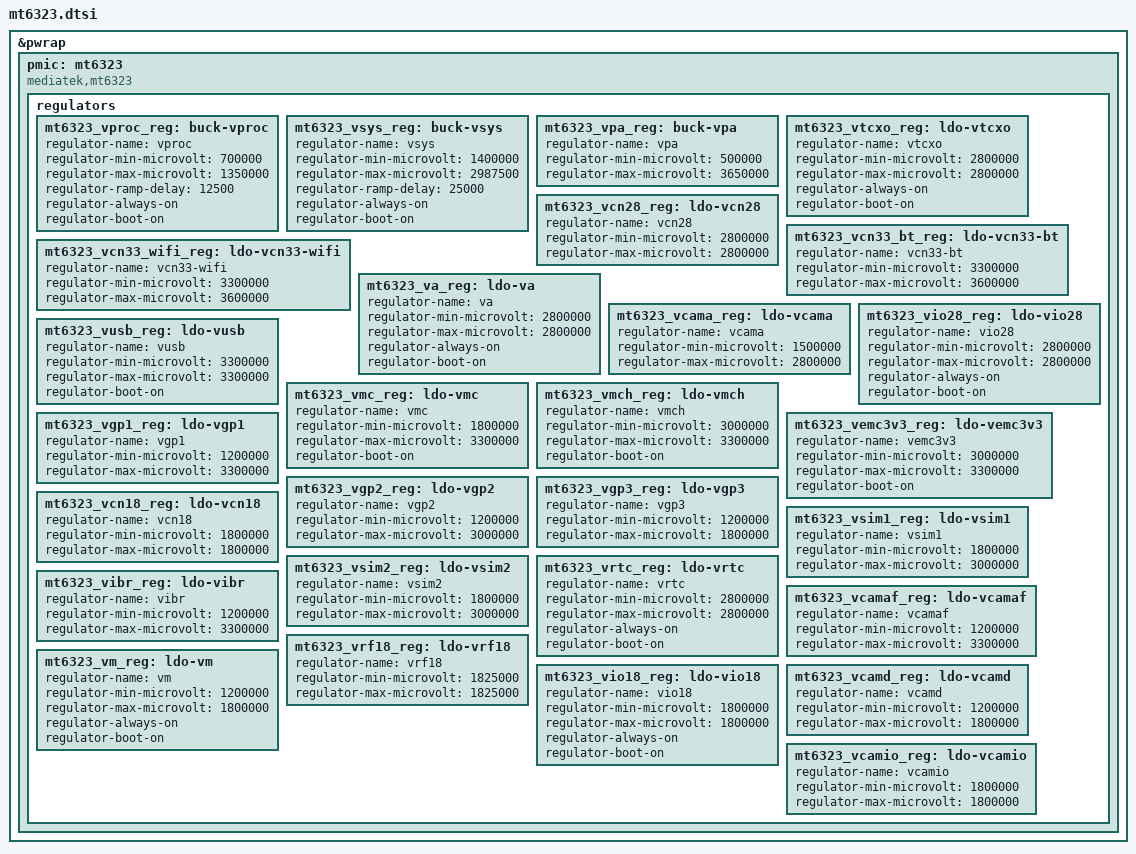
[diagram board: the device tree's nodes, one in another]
// SPDX-License-Identifier: GPL-2.0
/*
 * Copyright (c) 2017-2018 MediaTek Inc.
 * Author: John Crispin <john@phrozen.org>
 *	   Sean Wang <sean.wang@mediatek.com>
 * Copyright (c) 2026 Ben Grisdale <bengris32@protonmail.ch>
 */

&pwrap {
	pmic: mt6323 {
		compatible = "mediatek,mt6323";

		regulators {
			mt6323_vproc_reg: buck-vproc {
				regulator-name = "vproc";
				regulator-min-microvolt = <700000>;
				regulator-max-microvolt = <1350000>;
				regulator-ramp-delay = <12500>;
				regulator-always-on;
				regulator-boot-on;
			};

			mt6323_vsys_reg: buck-vsys {
				regulator-name = "vsys";
				regulator-min-microvolt = <1400000>;
				regulator-max-microvolt = <2987500>;
				regulator-ramp-delay = <25000>;
				regulator-always-on;
				regulator-boot-on;
			};

			mt6323_vpa_reg: buck-vpa {
				regulator-name = "vpa";
				regulator-min-microvolt = <500000>;
				regulator-max-microvolt = <3650000>;
			};

			mt6323_vtcxo_reg: ldo-vtcxo {
				regulator-name = "vtcxo";
				regulator-min-microvolt = <2800000>;
				regulator-max-microvolt = <2800000>;
				regulator-always-on;
				regulator-boot-on;
			};

			mt6323_vcn28_reg: ldo-vcn28 {
				regulator-name = "vcn28";
				regulator-min-microvolt = <2800000>;
				regulator-max-microvolt = <2800000>;
			};

			mt6323_vcn33_bt_reg: ldo-vcn33-bt {
				regulator-name = "vcn33-bt";
				regulator-min-microvolt = <3300000>;
				regulator-max-microvolt = <3600000>;
			};

			mt6323_vcn33_wifi_reg: ldo-vcn33-wifi {
				regulator-name = "vcn33-wifi";
				regulator-min-microvolt = <3300000>;
				regulator-max-microvolt = <3600000>;
			};

			mt6323_va_reg: ldo-va {
				regulator-name = "va";
				regulator-min-microvolt = <2800000>;
				regulator-max-microvolt = <2800000>;
				regulator-always-on;
				regulator-boot-on;
			};

			mt6323_vcama_reg: ldo-vcama {
				regulator-name = "vcama";
				regulator-min-microvolt = <1500000>;
				regulator-max-microvolt = <2800000>;
			};

			mt6323_vio28_reg: ldo-vio28 {
				regulator-name = "vio28";
				regulator-min-microvolt = <2800000>;
				regulator-max-microvolt = <2800000>;
				regulator-always-on;
				regulator-boot-on;
			};

			mt6323_vusb_reg: ldo-vusb {
				regulator-name = "vusb";
				regulator-min-microvolt = <3300000>;
				regulator-max-microvolt = <3300000>;
				regulator-boot-on;
			};

			mt6323_vmc_reg: ldo-vmc {
				regulator-name = "vmc";
				regulator-min-microvolt = <1800000>;
				regulator-max-microvolt = <3300000>;
				regulator-boot-on;
			};

			mt6323_vmch_reg: ldo-vmch {
				regulator-name = "vmch";
				regulator-min-microvolt = <3000000>;
				regulator-max-microvolt = <3300000>;
				regulator-boot-on;
			};

			mt6323_vemc3v3_reg: ldo-vemc3v3 {
				regulator-name = "vemc3v3";
				regulator-min-microvolt = <3000000>;
				regulator-max-microvolt = <3300000>;
				regulator-boot-on;
			};

			mt6323_vgp1_reg: ldo-vgp1 {
				regulator-name = "vgp1";
				regulator-min-microvolt = <1200000>;
				regulator-max-microvolt = <3300000>;
			};

			mt6323_vgp2_reg: ldo-vgp2 {
				regulator-name = "vgp2";
				regulator-min-microvolt = <1200000>;
				regulator-max-microvolt = <3000000>;
			};

			mt6323_vgp3_reg: ldo-vgp3 {
				regulator-name = "vgp3";
				regulator-min-microvolt = <1200000>;
				regulator-max-microvolt = <1800000>;
			};

			mt6323_vcn18_reg: ldo-vcn18 {
				regulator-name = "vcn18";
				regulator-min-microvolt = <1800000>;
				regulator-max-microvolt = <1800000>;
			};

			mt6323_vsim1_reg: ldo-vsim1 {
				regulator-name = "vsim1";
				regulator-min-microvolt = <1800000>;
				regulator-max-microvolt = <3000000>;
			};

			mt6323_vsim2_reg: ldo-vsim2 {
				regulator-name = "vsim2";
				regulator-min-microvolt = <1800000>;
				regulator-max-microvolt = <3000000>;
			};

			mt6323_vrtc_reg: ldo-vrtc {
				regulator-name = "vrtc";
				regulator-min-microvolt = <2800000>;
				regulator-max-microvolt = <2800000>;
				regulator-always-on;
				regulator-boot-on;
			};

			mt6323_vcamaf_reg: ldo-vcamaf {
				regulator-name = "vcamaf";
				regulator-min-microvolt = <1200000>;
				regulator-max-microvolt = <3300000>;
			};

			mt6323_vibr_reg: ldo-vibr {
				regulator-name = "vibr";
				regulator-min-microvolt = <1200000>;
				regulator-max-microvolt = <3300000>;
			};

			mt6323_vrf18_reg: ldo-vrf18 {
				regulator-name = "vrf18";
				regulator-min-microvolt = <1825000>;
				regulator-max-microvolt = <1825000>;
			};

			mt6323_vm_reg: ldo-vm {
				regulator-name = "vm";
				regulator-min-microvolt = <1200000>;
				regulator-max-microvolt = <1800000>;
				regulator-always-on;
				regulator-boot-on;
			};

			mt6323_vio18_reg: ldo-vio18 {
				regulator-name = "vio18";
				regulator-min-microvolt = <1800000>;
				regulator-max-microvolt = <1800000>;
				regulator-always-on;
				regulator-boot-on;
			};

			mt6323_vcamd_reg: ldo-vcamd {
				regulator-name = "vcamd";
				regulator-min-microvolt = <1200000>;
				regulator-max-microvolt = <1800000>;
			};

			mt6323_vcamio_reg: ldo-vcamio {
				regulator-name = "vcamio";
				regulator-min-microvolt = <1800000>;
				regulator-max-microvolt = <1800000>;
			};
		};
	};
};
